# STM32WB55 register map
File version: 2.0
CPU: CM4 r0p1, little endian, MPU, FPU, 4 interrupt priority bits
Registers are 32-bit, read-write, reset 0x0 unless marked. A register's access mark holds for its fields unless they carry their own. Offsets are from the block's base; [hi:lo] are bit positions; {n}, {i} and the like mark numbered series; 'fields as' and 'values as' point back to an identical list.

## ADC_Common — ADC common registers
Base 0x50040300
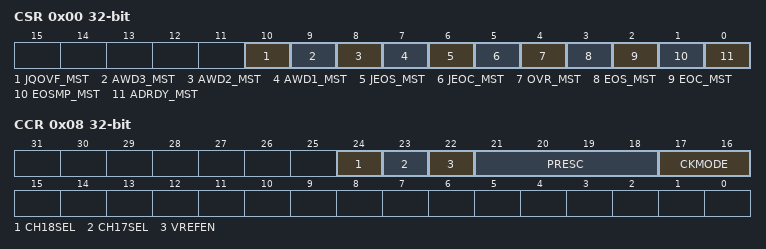
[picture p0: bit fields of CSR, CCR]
0x00 CSR ro — ADC common status register
  [10] JQOVF_MST — Injected Context Queue Overflow flag of the master ADC
  [9] AWD3_MST — Analog watchdog 3 flag of the master ADC
  [8] AWD2_MST — Analog watchdog 2 flag of the master ADC
  [7] AWD1_MST — Analog watchdog 1 flag of the master ADC
  [6] JEOS_MST — End of injected sequence flag of the master ADC
  [5] JEOC_MST — End of injected conversion flag of the master ADC
  [4] OVR_MST — Overrun flag of the master ADC
  [3] EOS_MST — End of regular sequence flag of the master ADC
  [2] EOC_MST — End of regular conversion flag of the master ADC
  [1] EOSMP_MST — End of Sampling phase flag of the master ADC
  [0] ADRDY_MST — master ADC ready
0x08 CCR — ADC common control register
  [24] CH18SEL — CH18 selection (Vbat)
  [23] CH17SEL — CH17 selection (temperature)
  [22] VREFEN — Vrefint enable
  [21:18] PRESC — ADC prescaler
  [17:16] CKMODE — ADC clock mode

## GPIOH — General-purpose I/Os
Base 0x48001C00
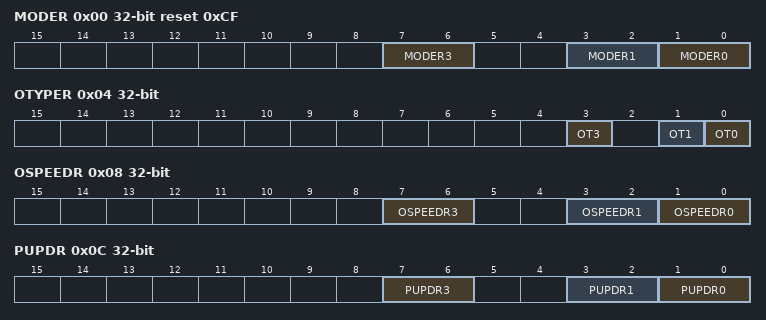
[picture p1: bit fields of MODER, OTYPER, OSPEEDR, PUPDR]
0x00 MODER reset 0xCF — GPIO port mode register
  [all] fields
    0=Input mode (reset state); 1=Output (General purpose output mode); 2=Alternate function mode; 3=Analog mode
  [7:6] MODER3 — Port x configuration bits (y = 0..15)
  [3:2] MODER1 — Port x configuration bits (y = 0..15)
  [1:0] MODER0 — Port x configuration bits (y = 0..15)
0x04 OTYPER — GPIO port output type register
  [all] fields
    0=PushPull (Output push-pull (reset state)); 1=OpenDrain (Output open-drain)
  [3] OT3 — Port x configuration bits (y = 0..15)
  [1] OT1 — Port x configuration bits (y = 0..15)
  [0] OT0 — Port x configuration bits (y = 0..15)
0x08 OSPEEDR — GPIO port output speed register
  [all] fields
    0=LowSpeed; 1=MediumSpeed; 2=HighSpeed; 3=VeryHighSpeed
  [7:6] OSPEEDR3 — Port x configuration bits (y = 0..15)
  [3:2] OSPEEDR1 — Port x configuration bits (y = 0..15)
  [1:0] OSPEEDR0 — Port x configuration bits (y = 0..15)
0x0C PUPDR — GPIO port pull-up/pull-down register
  [all] fields
    0=Floating (No pull-up, pull-down); 1=PullUp; 2=PullDown
  [7:6] PUPDR3 — Port x configuration bits (y = 0..15)
  [3:2] PUPDR1 — Port x configuration bits (y = 0..15)
  [1:0] PUPDR0 — Port x configuration bits (y = 0..15)
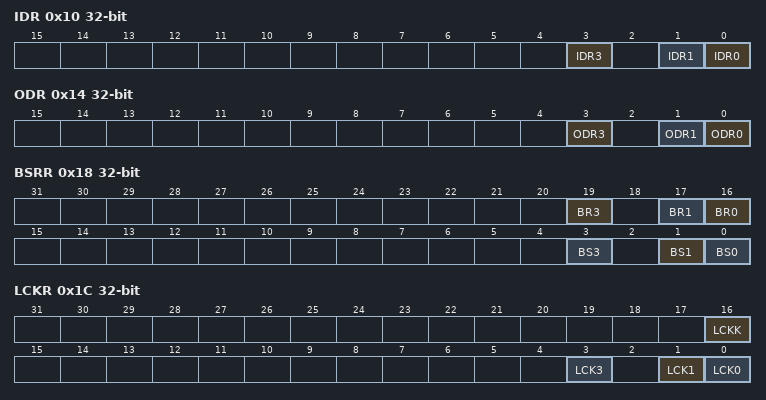
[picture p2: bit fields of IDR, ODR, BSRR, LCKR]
0x10 IDR ro — GPIO port input data register
  [all] fields
    0=Low (Input is logic low); 1=High (Input is logic high)
  [3] IDR3 — Port input data (y = 0..15)
  [1] IDR1 — Port input data (y = 0..15)
  [0] IDR0 — Port input data (y = 0..15)
0x14 ODR — GPIO port output data register
  [all] fields
    0=Low (Set output to logic low); 1=High (Set output to logic high)
  [3] ODR3 — Port output data (y = 0..15)
  [1] ODR1 — Port output data (y = 0..15)
  [0] ODR0 — Port output data (y = 0..15)
0x18 BSRR wo — GPIO port bit set/reset register
  [19] BR3 — Port x reset bit y (y = 0..15)
    1=Resets the corresponding ODRx bit
  [17] BR1 — Port x reset bit y (y = 0..15)
    1=Resets the corresponding ODRx bit
  [16] BR0 — Port x set bit y (y= 0..15)
    1=Resets the corresponding ODRx bit
  [3] BS3 — Port x set bit y (y= 0..15)
    1=Set (Sets the corresponding ODRx bit)
  [1] BS1 — Port x set bit y (y= 0..15)
    1=Set (Sets the corresponding ODRx bit)
  [0] BS0 — Port x set bit y (y= 0..15)
    1=Set (Sets the corresponding ODRx bit)
0x1C LCKR — GPIO port configuration lock register
  [16] LCKK — Port x lock bit y (y= 0..15)
    0=NotActive (Port configuration lock key not active); 1=Active (Port configuration lock key active)
  [3] LCK3 — Port x lock bit y (y= 0..15)
    0=Unlocked (Port configuration not locked); 1=Locked (Port configuration locked)
  [1] LCK1 — Port x lock bit y (y= 0..15)
    values as LCK3
  [0] LCK0 — Port x lock bit y (y= 0..15)
    values as LCK3
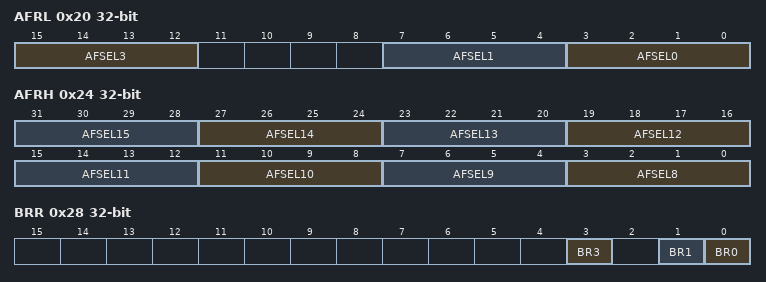
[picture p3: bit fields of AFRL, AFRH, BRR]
0x20 AFRL — GPIO alternate function low register
  [15:12] AFSEL3 — Alternate function selection for port x bit y (y = 0..7)
  [7:4] AFSEL1 — Alternate function selection for port x bit y (y = 0..7)
  [3:0] AFSEL0 — Alternate function selection for port x bit y (y = 0..7)
0x24 AFRH — GPIO alternate function high register
  [4n-29:4n-32] AFSEL{n} (n=8..15) — Alternate function selection for port x bit y (y = 8..15)
0x28 BRR wo — port bit reset register
  [3] BR3 — Port Reset bit
    1=Resets the corresponding ODRx bit
  [1] BR1 — Port Reset bit
    1=Resets the corresponding ODRx bit
  [0] BR0 — Port Reset bit
    0=No action on the corresponding ODx bit; 1=Reset the ODx bit
